AUTOSAR XML (schema 4-2-2)
package /AUTOSAR_NvM/PortInterfaces
  6 x client server interface, all with is-service=true:
    NvMAdmin
      operation SetBlockProtection: possible-error=NvMAdmin/E_NOT_OK
        arg ProtectionEnabled: type=boolean, direction=IN
      error E_NOT_OK: error-code=1
    NvMMirror
      operation ReadRamBlockFromNvM: possible-error=NvMMirror/E_NOT_OK
        arg SrcPtr: type=NvM_Rb_VoidPtr, direction=IN
      operation WriteRamBlockToNvM: possible-error=NvMMirror/E_NOT_OK
        arg DstPtr: type=NvM_Rb_VoidPtr, direction=IN
      error E_NOT_OK: error-code=1
    NvMNotifyInitBlock
      operation InitBlock: possible-error=NvMNotifyInitBlock/E_NOT_OK
      error E_NOT_OK: error-code=1
    NvMNotifyJobFinished
      operation JobFinished: possible-error=NvMNotifyJobFinished/E_NOT_OK
        arg ServiceId: type=uint8, direction=IN
        arg JobResult: type=NvM_RequestResultType, direction=IN
      error E_NOT_OK: error-code=1
    NvMRbNotifyJobStarted
      operation JobStarted
        arg ServiceId: type=uint8, direction=IN
    NvMService
      9 x operation, all with possible-error=NvMService/E_NOT_OK:
        EraseBlock
        GetDataIndex
          arg DataIndexPtr: type=uint8, direction=OUT
        GetErrorStatus
          arg RequestResultPtr: type=NvM_RequestResultType, direction=OUT
        InvalidateNvBlock
        ReadBlock
          arg DstPtr: type=NvM_Rb_VoidPtr, direction=IN
        RestoreBlockDefaults
          arg DstPtr: type=NvM_Rb_VoidPtr, direction=IN
        SetDataIndex
          arg DataIndex: type=uint8, direction=IN
        SetRamBlockStatus
          arg BlockChanged: type=boolean, direction=IN
        WriteBlock
          arg SrcPtr: type=NvM_Rb_ConstVoidPtr, direction=IN
      error E_NOT_OK: error-code=1
package /AUTOSAR_NvM/SwcImplementations
  swc implementation NvM: programming-language=C, swc-bsw-mapping=NvM, vendor-id=6, behavior=NVRAMManager
package /AUTOSAR_NvM/SwComponentTypes
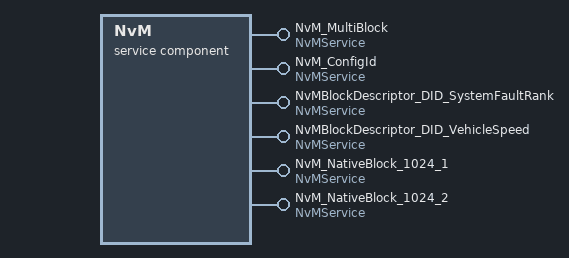
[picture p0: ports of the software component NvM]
  service sw component type NvM
    6 x provide port, all with provided-interface=NvMService:
      NvM_MultiBlock
      NvM_ConfigId
      NvMBlockDescriptor_DID_SystemFaultRank
      NvMBlockDescriptor_DID_VehicleSpeed
      NvM_NativeBlock_1024_1
      NvM_NativeBlock_1024_2
    behavior NVRAMManager
      54 x operation invoked event:
        EENB_NvM_MultiBlock: start-on-event=EraseNvBlock, operation=NvM_MultiBlock.EraseBlock
        EGDI_NvM_MultiBlock: start-on-event=GetDataIndex, operation=NvM_MultiBlock.GetDataIndex
        EGES_NvM_MultiBlock: start-on-event=GetErrorStatus, operation=NvM_MultiBlock.GetErrorStatus
        EINB_NvM_MultiBlock: start-on-event=InvalidateNvBlock, operation=NvM_MultiBlock.InvalidateNvBlock
        ERBL_NvM_MultiBlock: start-on-event=ReadBlock, operation=NvM_MultiBlock.ReadBlock
        ERBD_NvM_MultiBlock: start-on-event=RestoreBlockDefaults, operation=NvM_MultiBlock.RestoreBlockDefaults
        ESDI_NvM_MultiBlock: start-on-event=SetDataIndex, operation=NvM_MultiBlock.SetDataIndex
        ESRS_NvM_MultiBlock: start-on-event=SetRamBlockStatus, operation=NvM_MultiBlock.SetRamBlockStatus
        EWBL_NvM_MultiBlock: start-on-event=WriteBlock, operation=NvM_MultiBlock.WriteBlock
        EENB_NvM_ConfigId: start-on-event=EraseNvBlock, operation=NvM_ConfigId.EraseBlock
        EGDI_NvM_ConfigId: start-on-event=GetDataIndex, operation=NvM_ConfigId.GetDataIndex
        EGES_NvM_ConfigId: start-on-event=GetErrorStatus, operation=NvM_ConfigId.GetErrorStatus
        EINB_NvM_ConfigId: start-on-event=InvalidateNvBlock, operation=NvM_ConfigId.InvalidateNvBlock
        ERBL_NvM_ConfigId: start-on-event=ReadBlock, operation=NvM_ConfigId.ReadBlock
        ERBD_NvM_ConfigId: start-on-event=RestoreBlockDefaults, operation=NvM_ConfigId.RestoreBlockDefaults
        ESDI_NvM_ConfigId: start-on-event=SetDataIndex, operation=NvM_ConfigId.SetDataIndex
        ESRS_NvM_ConfigId: start-on-event=SetRamBlockStatus, operation=NvM_ConfigId.SetRamBlockStatus
        EWBL_NvM_ConfigId: start-on-event=WriteBlock, operation=NvM_ConfigId.WriteBlock
        EENB_NvMBlockDescriptor_DID_SystemFaultRank: start-on-event=EraseNvBlock, operation=NvMBlockDescriptor_DID_SystemFaultRank.EraseBlock
        EGDI_NvMBlockDescriptor_DID_SystemFaultRank: start-on-event=GetDataIndex, operation=NvMBlockDescriptor_DID_SystemFaultRank.GetDataIndex
        EGES_NvMBlockDescriptor_DID_SystemFaultRank: start-on-event=GetErrorStatus, operation=NvMBlockDescriptor_DID_SystemFaultRank.GetErrorStatus
        EINB_NvMBlockDescriptor_DID_SystemFaultRank: start-on-event=InvalidateNvBlock, operation=NvMBlockDescriptor_DID_SystemFaultRank.InvalidateNvBlock
        ERBL_NvMBlockDescriptor_DID_SystemFaultRank: start-on-event=ReadBlock, operation=NvMBlockDescriptor_DID_SystemFaultRank.ReadBlock
        ERBD_NvMBlockDescriptor_DID_SystemFaultRank: start-on-event=RestoreBlockDefaults, operation=NvMBlockDescriptor_DID_SystemFaultRank.RestoreBlockDefaults
        ESDI_NvMBlockDescriptor_DID_SystemFaultRank: start-on-event=SetDataIndex, operation=NvMBlockDescriptor_DID_SystemFaultRank.SetDataIndex
        ESRS_NvMBlockDescriptor_DID_SystemFaultRank: start-on-event=SetRamBlockStatus, operation=NvMBlockDescriptor_DID_SystemFaultRank.SetRamBlockStatus
        EWBL_NvMBlockDescriptor_DID_SystemFaultRank: start-on-event=WriteBlock, operation=NvMBlockDescriptor_DID_SystemFaultRank.WriteBlock
        EENB_NvMBlockDescriptor_DID_VehicleSpeed: start-on-event=EraseNvBlock, operation=NvMBlockDescriptor_DID_VehicleSpeed.EraseBlock
        EGDI_NvMBlockDescriptor_DID_VehicleSpeed: start-on-event=GetDataIndex, operation=NvMBlockDescriptor_DID_VehicleSpeed.GetDataIndex
        EGES_NvMBlockDescriptor_DID_VehicleSpeed: start-on-event=GetErrorStatus, operation=NvMBlockDescriptor_DID_VehicleSpeed.GetErrorStatus
        EINB_NvMBlockDescriptor_DID_VehicleSpeed: start-on-event=InvalidateNvBlock, operation=NvMBlockDescriptor_DID_VehicleSpeed.InvalidateNvBlock
        ERBL_NvMBlockDescriptor_DID_VehicleSpeed: start-on-event=ReadBlock, operation=NvMBlockDescriptor_DID_VehicleSpeed.ReadBlock
        ERBD_NvMBlockDescriptor_DID_VehicleSpeed: start-on-event=RestoreBlockDefaults, operation=NvMBlockDescriptor_DID_VehicleSpeed.RestoreBlockDefaults
        ESDI_NvMBlockDescriptor_DID_VehicleSpeed: start-on-event=SetDataIndex, operation=NvMBlockDescriptor_DID_VehicleSpeed.SetDataIndex
        ESRS_NvMBlockDescriptor_DID_VehicleSpeed: start-on-event=SetRamBlockStatus, operation=NvMBlockDescriptor_DID_VehicleSpeed.SetRamBlockStatus
        EWBL_NvMBlockDescriptor_DID_VehicleSpeed: start-on-event=WriteBlock, operation=NvMBlockDescriptor_DID_VehicleSpeed.WriteBlock
        EENB_NvM_NativeBlock_1024_1: start-on-event=EraseNvBlock, operation=NvM_NativeBlock_1024_1.EraseBlock
        EGDI_NvM_NativeBlock_1024_1: start-on-event=GetDataIndex, operation=NvM_NativeBlock_1024_1.GetDataIndex
        EGES_NvM_NativeBlock_1024_1: start-on-event=GetErrorStatus, operation=NvM_NativeBlock_1024_1.GetErrorStatus
        EINB_NvM_NativeBlock_1024_1: start-on-event=InvalidateNvBlock, operation=NvM_NativeBlock_1024_1.InvalidateNvBlock
        ERBL_NvM_NativeBlock_1024_1: start-on-event=ReadBlock, operation=NvM_NativeBlock_1024_1.ReadBlock
        ERBD_NvM_NativeBlock_1024_1: start-on-event=RestoreBlockDefaults, operation=NvM_NativeBlock_1024_1.RestoreBlockDefaults
        ESDI_NvM_NativeBlock_1024_1: start-on-event=SetDataIndex, operation=NvM_NativeBlock_1024_1.SetDataIndex
        ESRS_NvM_NativeBlock_1024_1: start-on-event=SetRamBlockStatus, operation=NvM_NativeBlock_1024_1.SetRamBlockStatus
        EWBL_NvM_NativeBlock_1024_1: start-on-event=WriteBlock, operation=NvM_NativeBlock_1024_1.WriteBlock
        EENB_NvM_NativeBlock_1024_2: start-on-event=EraseNvBlock, operation=NvM_NativeBlock_1024_2.EraseBlock
        EGDI_NvM_NativeBlock_1024_2: start-on-event=GetDataIndex, operation=NvM_NativeBlock_1024_2.GetDataIndex
        EGES_NvM_NativeBlock_1024_2: start-on-event=GetErrorStatus, operation=NvM_NativeBlock_1024_2.GetErrorStatus
        EINB_NvM_NativeBlock_1024_2: start-on-event=InvalidateNvBlock, operation=NvM_NativeBlock_1024_2.InvalidateNvBlock
        ERBL_NvM_NativeBlock_1024_2: start-on-event=ReadBlock, operation=NvM_NativeBlock_1024_2.ReadBlock
        ERBD_NvM_NativeBlock_1024_2: start-on-event=RestoreBlockDefaults, operation=NvM_NativeBlock_1024_2.RestoreBlockDefaults
        ESDI_NvM_NativeBlock_1024_2: start-on-event=SetDataIndex, operation=NvM_NativeBlock_1024_2.SetDataIndex
        ESRS_NvM_NativeBlock_1024_2: start-on-event=SetRamBlockStatus, operation=NvM_NativeBlock_1024_2.SetRamBlockStatus
        EWBL_NvM_NativeBlock_1024_2: start-on-event=WriteBlock, operation=NvM_NativeBlock_1024_2.WriteBlock
      port-api-options:
        {enable-take-address=false, indirect-api=false, port-defined-argument-value{value=0, value-type=NvM_BlockIdType}, port=NvM_MultiBlock}
        {enable-take-address=false, indirect-api=false, port-defined-argument-value{value=1, value-type=NvM_BlockIdType}, port=NvM_ConfigId}
        {enable-take-address=false, indirect-api=false, port-defined-argument-value{value=3, value-type=NvM_BlockIdType}, port=NvMBlockDescriptor_DID_SystemFaultRank}
        {enable-take-address=false, indirect-api=false, port-defined-argument-value{value=4, value-type=NvM_BlockIdType}, port=NvMBlockDescriptor_DID_VehicleSpeed}
        {enable-take-address=false, indirect-api=false, port-defined-argument-value{value=12, value-type=NvM_BlockIdType}, port=NvM_NativeBlock_1024_1}
        {enable-take-address=false, indirect-api=false, port-defined-argument-value{value=13, value-type=NvM_BlockIdType}, port=NvM_NativeBlock_1024_2}
      11 x runnable:
        EraseNvBlock: can-be-invoked-concurrently=true, symbol=NvM_EraseNvBlock
        GetDataIndex: can-be-invoked-concurrently=true, symbol=NvM_GetDataIndex
        GetErrorStatus: can-be-invoked-concurrently=true, symbol=NvM_GetErrorStatus
        InvalidateNvBlock: can-be-invoked-concurrently=true, symbol=NvM_InvalidateNvBlock
        ReadBlock: can-be-invoked-concurrently=true, symbol=NvM_ReadBlock
        RestoreBlockDefaults: can-be-invoked-concurrently=true, symbol=NvM_RestoreBlockDefaults
        SetBlockProtection: can-be-invoked-concurrently=true, symbol=NvM_SetBlockProtection
        SetDataIndex: can-be-invoked-concurrently=true, symbol=NvM_SetDataIndex
        SetRamBlockStatus: can-be-invoked-concurrently=true, symbol=NvM_SetRamBlockStatus
        WriteBlock: can-be-invoked-concurrently=true, symbol=NvM_WriteBlock
        MainFunction: symbol=NvM_MainFunction
